# RE01_1500KB register map
Vendor: Renesas Electronics Corporation; Series: RE01_1500KB; File version: 1.20
CPU: CM0PLUS r0p1, little endian, MPU, no FPU, VTOR, 2 interrupt priority bits
Registers are 8-bit, read-write, reset 0x0 unless marked. A register's access mark holds for its fields unless they carry their own. Offsets are from the block's base; [hi:lo] are bit positions; {n}, {i} and the like mark numbered series; 'fields as' and 'values as' point back to an identical list.

## MTDV — Motor Driver Control Circuit
Base 0x40084800
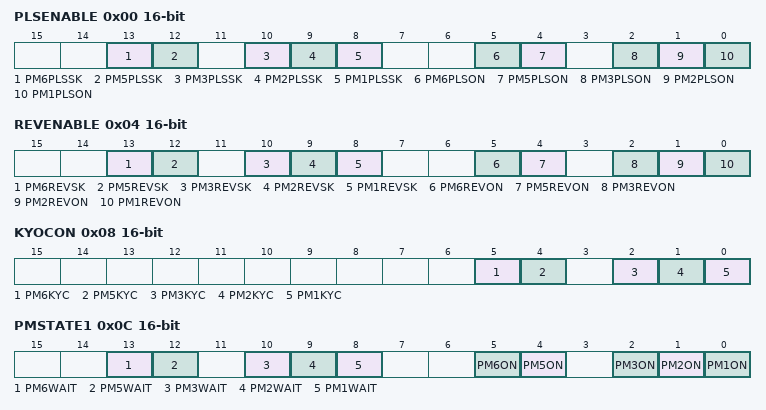
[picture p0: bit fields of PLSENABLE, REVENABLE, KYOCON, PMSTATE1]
0x00 PLSENABLE 16-bit wo — Plus Enable Imput Resister
  [13] PM6PLSSK, [12] PM5PLSSK, [10] PM3PLSSK, [9] PM2PLSSK, [8] PM1PLSSK, [5] PM6PLSON, [4] PM5PLSON, [2] PM3PLSON, [1] PM2PLSON, [0] PM1PLSON
0x04 REVENABLE 16-bit wo — Reverse Enable Imput Resister
  [13] PM6REVSK, [12] PM5REVSK, [10] PM3REVSK, [9] PM2REVSK, [8] PM1REVSK, [5] PM6REVON, [4] PM5REVON, [2] PM3REVON, [1] PM2REVON, [0] PM1REVON
0x08 KYOCON 16-bit wo — Pulse Polarity Reverse Register
  [5] PM6KYC, [4] PM5KYC, [2] PM3KYC, [1] PM2KYC, [0] PM1KYC
0x0C PMSTATE1 16-bit ro — PM Status Register1
  [13] PM6WAIT, [12] PM5WAIT, [10] PM3WAIT, [9] PM2WAIT, [8] PM1WAIT, [5] PM6ON, [4] PM5ON, [2] PM3ON, [1] PM2ON, [0] PM1ON
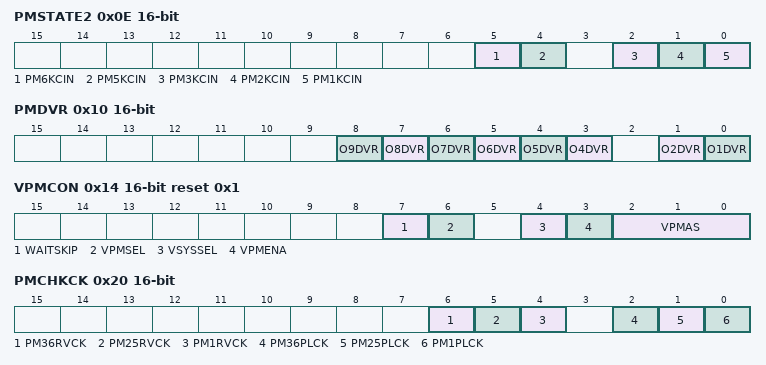
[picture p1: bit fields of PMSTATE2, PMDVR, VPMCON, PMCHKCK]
0x0E PMSTATE2 16-bit ro — PM Status Register2
  [5] PM6KCIN, [4] PM5KCIN, [2] PM3KCIN, [1] PM2KCIN, [0] PM1KCIN
0x10 PMDVR 16-bit — Driver Direct Control Register
  [n-1] O{n}DVR (n=4..9), [1] O2DVR, [0] O1DVR
0x14 VPMCON 16-bit reset 0x1 — VPM Control Register
  [7] WAITSKIP
  [6] VPMSEL
  [4] VSYSSEL
  [3] VPMENA
  [2:0] VPMAS
    0=1.6[V]; 1=1.9[V]; 2=2.0[V]; 3=2.1[V]; 4=2.2[V]; 5=2.3[V]; 6=2.4[V]; 7=2.5[V]
0x18 RESREG 16-bit — Built-in Registance Setting Register
  [2:0] PM1RES
    0=000; 1=25K ohm; 2=50K ohm; 3=75K ohm; 4=100K ohm; 5=150K ohm; 6=175K ohm; 7=200K ohm
0x1C PMCHKTM 16-bit reset 0x40 — Interval Time Setting Register
  [9:0] CHK
0x20 PMCHKCK 16-bit — Interval Time Setting Timer Selection Register
  [6] PM36RVCK, [5] PM25RVCK, [4] PM1RVCK, [2] PM36PLCK, [1] PM25PLCK, [0] PM1PLCK
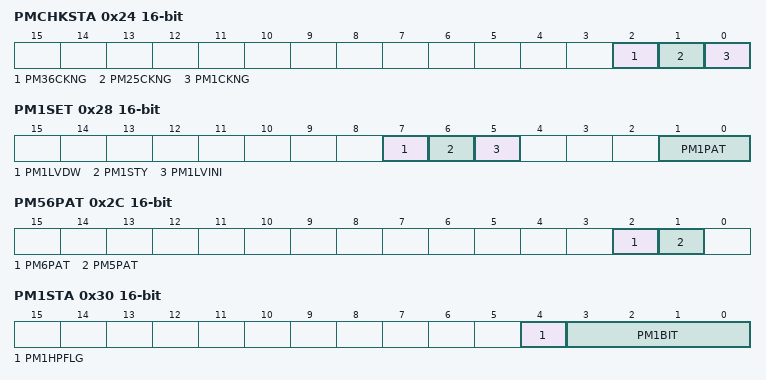
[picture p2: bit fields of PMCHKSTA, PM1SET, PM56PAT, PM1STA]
0x24 PMCHKSTA 16-bit ro — PM Timer Status Register
  [2] PM36CKNG, [1] PM25CKNG, [0] PM1CKNG
0x28 PM1SET 16-bit — PM1 Setting Register
  [7] PM1LVDW
  [6] PM1STY
  [5] PM1LVINI
  [1:0] PM1PAT
    0=00; 1=01; 2=10; 3=11
0x2C PM56PAT 16-bit — PM 56 Correctionment Pulse Selection Register
  [2] PM6PAT, [1] PM5PAT
0x30 PM1STA 16-bit ro — PM1 Status Register
  [4] PM1HPFLG
  [3:0] PM1BIT — These bits are read as 0. The write value should be 0.
    0=(7.6x1=7.6us); 1=(7.6x2=15.2us); 2=(7.6x3=22.8us); 3=(7.6x4=30.4us); 4=(7.6x5=38.0us); 5=(7.6x6=45.6us); 6=(7.6x7=53.2us); 7=(7.6x8=60.8us); 8=(7.6x9=68.4us); 9=(7.6x10=76.0us); 10=(7.6x11=83.6us); 11=(7.6x12=91.2us); 12=(7.6x13=98.8us); 13=(7.6x14=106.4us); 14=(7.6x15=114.0us); 15=(7.6x16=121.6us
0x80 P1FPCT1ALL 16-bit reset 0x20 — PM1 Forward Pulse Full Length Setting Register
  [7:0] P1FPFL
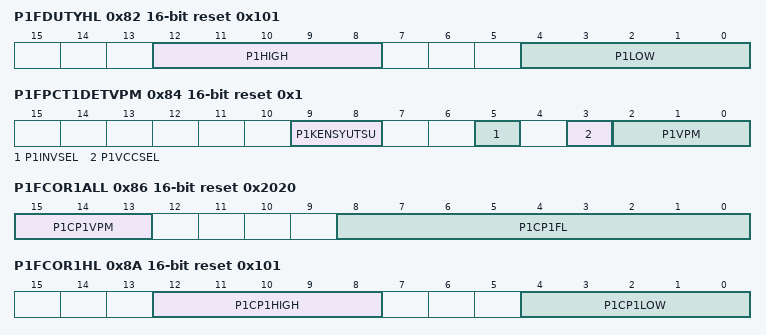
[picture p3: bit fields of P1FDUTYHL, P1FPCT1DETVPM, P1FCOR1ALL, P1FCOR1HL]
0x82 P1FDUTYHL 16-bit reset 0x101 — PMm Forward Pulse Duty Width Setting Register
  [12:8] P1HIGH, [4:0] P1LOW
0x84 P1FPCT1DETVPM 16-bit reset 0x1 — PM1 Rotate Ditection Setting Register
  [9:8] P1KENSYUTSU
    0=00; 1=01; 2=10; 3=11
  [5] P1INVSEL
  [3] P1VCCSEL
  [2:0] P1VPM
    0=VPM Output=1.6[V]; 1=VPM Output=1.9[V]; 2=VPM Output=2.0[V]; 3=VPM Output=2.1[V]; 4=VPM Output=2.2[V]; 5=VPM Output=2.3[V]; 6=VPM Output=2.4[V]; 7=VPM Output=2.5[V]
0x86 P1FCOR1ALL 16-bit reset 0x2020 — PM1 Correction Pulse 1 Full Length Setting Register
  [15:13] P1CP1VPM
    0=VPM Output=1.6[V]; 1=VPM Output=1.9[V](Default); 2=VPM Output=2.0[V]; 3=VPM Output=2.1[V]; 4=VPM Output=2.2[V]; 5=VPM Output=2.3[V]; 6=VPM Output=2.4[V]; 7=VPM Output=2.5[V]
  [8:0] P1CP1FL
0x88 P1FCOR1B 16-bit reset 0x1 — PM1 Correction Pulse 1 Beta Setting Register
  [8:0] P1CP1B
0x8A P1FCOR1HL 16-bit reset 0x101 — PM1 Correction Pulse 1 Duty Width Setting Register
  [12:8] P1CP1HIGH, [4:0] P1CP1LOW
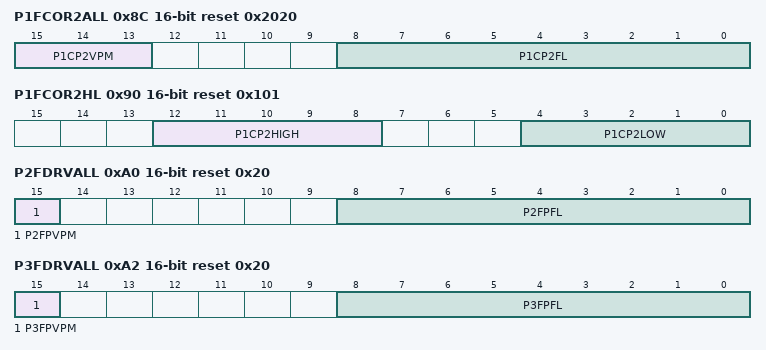
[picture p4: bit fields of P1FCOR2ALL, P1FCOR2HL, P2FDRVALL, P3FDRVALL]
0x8C P1FCOR2ALL 16-bit reset 0x2020 — PM1 Correction Pulse 2 Full Length Setting Register
  [15:13] P1CP2VPM
    values as P1FCOR1ALL.P1CP1VPM
  [8:0] P1CP2FL
0x8E P1FCOR2B 16-bit reset 0x1 — PM1 Correction Pulse 2 Beta Setting Register
  [8:0] P1CP2B
0x90 P1FCOR2HL 16-bit reset 0x101 — PM1 Correction Pulse 2 Duty Width Setting Register
  [12:8] P1CP2HIGH, [4:0] P1CP2LOW
0xA0 P2FDRVALL 16-bit reset 0x20 — PM2 Forward Rotation Pulse Full Length Setting Register
  [15] P2FPVPM, [8:0] P2FPFL
0xA2 P3FDRVALL 16-bit reset 0x20 — PM3 Forward Rotation Pulse Full Length Setting Register
  [15] P3FPVPM, [8:0] P3FPFL
0xA4 P2FDRVB 16-bit reset 0x1 — PM2 Forward Pulse Beta Setting Register
  [8:0] P2FPB
0xA6 P3FDRVB 16-bit reset 0x1 — PM3 Forward Pulse Beta Setting Register
  [8:0] P3FPB
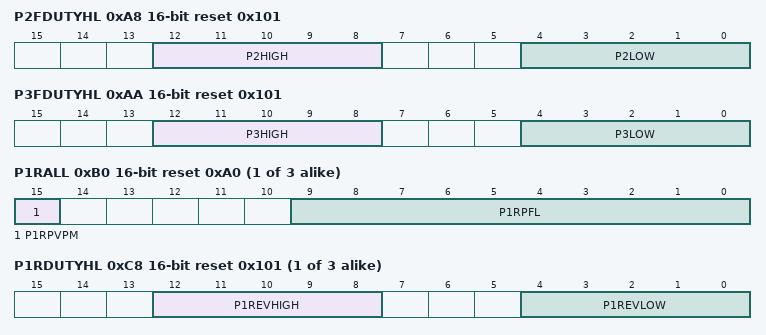
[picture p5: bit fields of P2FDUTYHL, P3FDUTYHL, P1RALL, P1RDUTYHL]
0xA8 P2FDUTYHL 16-bit reset 0x101 — PMm Forward Pulse Duty Width Setting Register
  [12:8] P2HIGH, [4:0] P2LOW
0xAA P3FDUTYHL 16-bit reset 0x101 — PMm Forward Pulse Duty Width Setting Register
  [12:8] P3HIGH, [4:0] P3LOW
{0xAE+2i} P{i}RALL 16-bit reset 0xA0 (i=1..3) — PM{i} Reversal Pulse Full Length Setting Register
  [15] P{i}RPVPM, [9:0] P{i}RPFL
{0xB4+2i} P{i}RP1SET 16-bit reset 0x10 (i=1..3) — PM{i} Reversal Pulse P1 Setting Register
  [7:0] P{i}REVP1
{0xBA+2i} P{i}RP2SET 16-bit reset 0x20 (i=1..3) — PM{i} Reversal Pulse P2 Setting Register
  [7:0] P{i}REVP2
{0xC0+2i} P{i}RP3SET 16-bit reset 0x40 (i=1..3) — PM{i} Reversal Pulse P3 Setting Register
  [8:0] P{i}REVP3
{0xC6+2i} P{i}RDUTYHL 16-bit reset 0x101 (i=1..3) — PM{i} Reversal Pulse Duty Width Setting Register
  [12:8] P{i}REVHIGH, [4:0] P{i}REVLOW
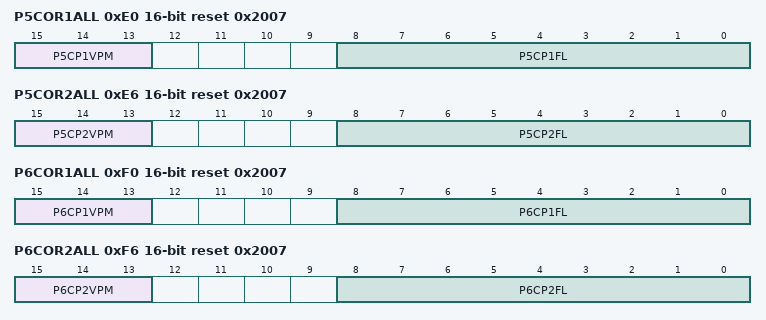
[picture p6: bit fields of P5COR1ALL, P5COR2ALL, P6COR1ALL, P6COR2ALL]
0xE0 P5COR1ALL 16-bit reset 0x2007 — PM5 Correction Pulse 1 Full Length Setting Register
  [15:13] P5CP1VPM
    values as P1FCOR1ALL.P1CP1VPM
  [8:0] P5CP1FL
0xE2 P5COR1P1SET 16-bit reset 0x1 — PM5 Correction Pulse 1 P1 Setting Register
  [7:0] P5CP1P1
0xE4 P5COR1P2SET 16-bit reset 0x1 — PM5 Correction Pulse 1 P2 Setting Register
  [7:0] P5CP1P2
0xE6 P5COR2ALL 16-bit reset 0x2007 — PM5 Correction Pulse 2 Full Length Setting Register
  [15:13] P5CP2VPM
    values as P1FCOR1ALL.P1CP1VPM
  [8:0] P5CP2FL
0xE8 P5COR2P1SET 16-bit reset 0x1 — PM5 Correction Pulse 2 P1 Setting Register
  [7:0] P5CP2P1
0xEA P5COR2P2SET 16-bit reset 0x1 — PM5 Correction Pulse 2 P2 Setting Register
  [7:0] P5CP2P2
0xF0 P6COR1ALL 16-bit reset 0x2007 — PM6 Correction Pulse 1 Full Length Setting Register
  [15:13] P6CP1VPM
    values as P1FCOR1ALL.P1CP1VPM
  [8:0] P6CP1FL
0xF2 P6COR1P1SET 16-bit reset 0x1 — PM6 Correction Pulse 1 P1 Setting Register
  [7:0] P6CP1P1
0xF4 P6COR1P2SET 16-bit reset 0x1 — PM6 Correction Pulse 1 P2 Setting Register
  [7:0] P6CP1P2
0xF6 P6COR2ALL 16-bit reset 0x2007 — PM6 Correction Pulse 2 Full Length Setting Register
  [15:13] P6CP2VPM
    values as P1FCOR1ALL.P1CP1VPM
  [8:0] P6CP2FL
0xF8 P6COR2P1SET 16-bit reset 0x1 — PM6 Correction Pulse 2 P1 Setting Register
  [7:0] P6CP2P1
0xFA P6COR2P2SET 16-bit reset 0x1 — PM6 Correction Pulse 2 P2 Setting Register
  [7:0] P6CP2P2
